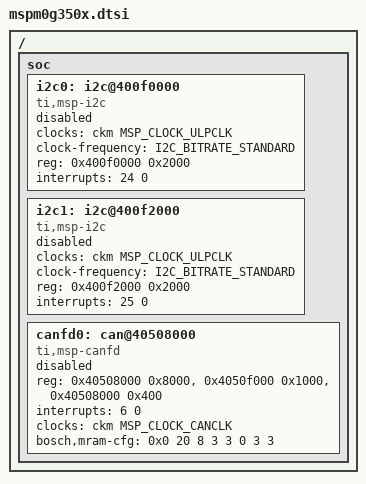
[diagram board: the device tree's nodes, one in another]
/*
 * Copyright (c) 2025 Texas Instruments
 *
 * SPDX-License-Identifier: Apache-2.0
 */

#include <ti/mspm0/g/mspm0g.dtsi>
#include <zephyr/dt-bindings/i2c/i2c.h>

/ {
	soc {
		i2c0: i2c@400f0000 {
			compatible = "ti,msp-i2c";
			clocks = <&ckm MSP_CLOCK_ULPCLK>;
			clock-frequency = <I2C_BITRATE_STANDARD>;
			#address-cells = <1>;
			#size-cells = <0>;
			reg = <0x400f0000 0x2000>;
			interrupts = <24 0>;
			status = "disabled";
		};

		i2c1: i2c@400f2000 {
			compatible = "ti,msp-i2c";
			clocks = <&ckm MSP_CLOCK_ULPCLK>;
			clock-frequency = <I2C_BITRATE_STANDARD>;
			#address-cells = <1>;
			#size-cells = <0>;
			reg = <0x400f2000 0x2000>;
			interrupts = <25 0>;
			status = "disabled";
		};

		canfd0: can@40508000 {
			compatible = "ti,msp-canfd";
			reg = <0x40508000 0x8000>, <0x4050f000 0x1000>, <0x40508000 0x400>;
			reg-names = "ti_canfd", "m_can", "message_ram";
			interrupts = <6 0>;
			clocks = <&ckm MSP_CLOCK_CANCLK>;
			bosch,mram-cfg = <0x0 20 8 3 3 0 3 3>;
			status = "disabled";
		};
	};
};
